# cyt2cl register map
Vendor: Cypress Semiconductor; Series: cyt2cl; File version: 1.0
CPU: CM4 r0p1, little endian, MPU, FPU, VTOR, 3 interrupt priority bits
Registers are 32-bit, read-write, reset 0x0 unless marked. A register's access mark holds for its fields unless they carry their own. Offsets are from the block's base; [hi:lo] are bit positions; lines under a group give offsets from that group; {n}, {i} and the like mark numbered series; <NAME> marks a mode.

## SMIF0 (part 1 of 2) — Serial Memory Interface
Base 0x40420000
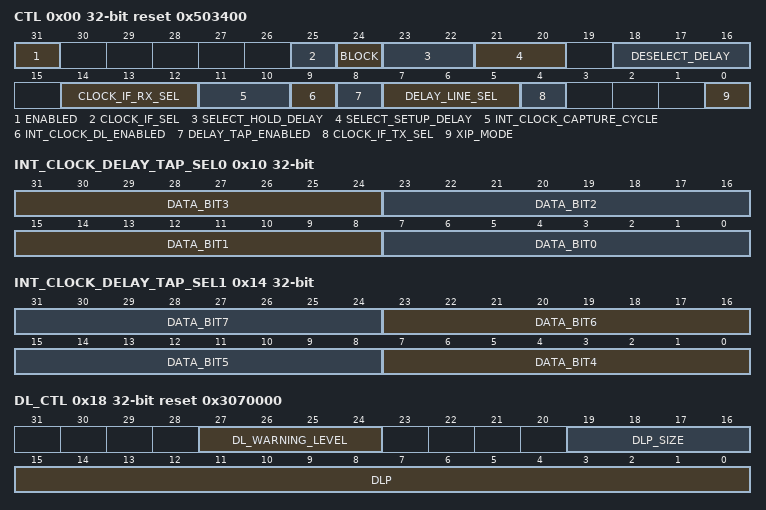
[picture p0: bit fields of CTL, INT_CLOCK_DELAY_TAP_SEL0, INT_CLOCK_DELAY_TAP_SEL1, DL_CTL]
0x00 CTL reset 0x503400 — Control
  [31] ENABLED — IP enable: '0': Disabled. All non-retention registers are reset to their default value when the IP is disabled. When the IP is disabled, the XIP accesses produce AHB-Lite bus errors and AXI error responses. '1': Enabled. Notes: - Before disabling or resetting the IP, SW should ensure that the IP is NOT busy (STATUS.BUSY is '0'), otherwise illegal interface transfers may occur. - After CTL.ENABLED is set to 1 it takes up to 20 clk_if cycles until the memory interface registers are realeased from reset.
    0=DISABLED (N/A); 1=ENABLED (N/A)
  [25] CLOCK_IF_SEL — Specifies the clock source for 'clk_if'. Must be 0 (clk_hf) before entering DeepSleep; can be returned to 1 (clk_pll) afterwards. '0': clk_hf is used to create clk_if '1': clk_pll is used to create clk_if
  [24] BLOCK — Specifies what happens for MMIO interface read accesses to an empty RX data FIFO or to a full TX format/data FIFO. This field is not used for test controller accesses.
    0=BUS_ERROR (0': Generate an AHB-Lite bus error. This option is useful when SW decides to use polling on STATUS.TR_BUSY to determine if a interface transfer is no longer busy (transfer is completed). This option adds SW complexity, but limits the number of AHB-Lite wait states (and limits ISR latency).); 1=WAIT_STATES (1': Introduce wait states. This setting potentially locks up the AHB-Lite infrastructure and may increase the CPU interrupt latency.This option is useful when SW performs TX/RX data FIFO accesses immediately after a command is setup using the TX format FIFO. This option has low SW complexity, but may result in a significant number of AHB-Lite wait states (and may increase ISR latency). This can be particularly true if ARB_MODE=1 and an MMIO access must wait a potentially long time behind a XIP access.)
  [23:22] SELECT_HOLD_DELAY — Specifies the duration between last 'spi_clk_out' edge to 'spi_select_out[]' becomes high/'1'): '0': 0 memory interface clock cycles + min. duration (see below). '1': 1 memory interface clock cycle + min. duration (see below). '2': 2 memory interface clock cycles + min. duration (see below). '3': 3 memory interface clock cycles + min. duration (see below). In addition to the number of cycles selected here there is a min. duration of: - 1/2 memory interface clock cycle (= 1 clk_if cycles) for SDR timing (CLOCK_IF_TX_SEL = 0) - 1/4 memory interface clock cycle (= 1/2 clk_if cycle) for DDR timing (CLOCK_IF_TX_SEL = 1)
  [21:20] SELECT_SETUP_DELAY — Specifies the duration between 'spi_select_out[]' becomes low/'0') to 1st 'spi_clk_out' edge: '0': 0 memory interface clock cycles + min. duration (see below). '1': 1 memory interface clock cycle + min. duration (see below). '2': 2 memory interface clock cycles + min. duration (see below). '3': 3 memory interface clock cycles + min. duration (see below). In addition to the number of cycles selected here there is a min. duration of: - 1 memory interface clock cycle (= 2 clk_if cycle) for SDR timing (CLOCK_IF_TX_SEL = 0) - 1/4 memory interface clock cycle (= 1/2 clk_if cycle) for DDR timing (CLOCK_IF_TX_SEL = 1)
  [18:16] DESELECT_DELAY — Specifies the minimum duration of SPI deselection ('spi_select_out[]' is high/'1') in between SPI transfers: '0': 1 memory interface clock cycle. '1': 2 memory interface clock cycles. '2': 3 memory interface clock cycles. '3': 4 memory interface clock cycles. '4': 5 memory interface clock cycles. '5': 6 memory interface clock cycles. '6': 7 memory interface clock cycles. '7': 8 memory interface clock cycles. During SPI deselection, 'spi_select_out[]' are '1'/inactive, 'spi_data_out[]' are '1' and 'spi_clk_out' is '0'/inactive.
  [14:12] CLOCK_IF_RX_SEL
  [11:10] INT_CLOCK_CAPTURE_CYCLE
  [9] INT_CLOCK_DL_ENABLED — Data Learning Enable for internal RX clock based on Data Learning Pattern. Only applies when CLOCK_IF_RX_SEL = [4..5] for selecting the internal clock based capture scheme and when DELAY_TAP_ENABLED = 1. Must be set to 0 otherwise. '0': Disabled. The delay line tap selections specified in registers INT_CLOCK_DELAY_TAP_SEL0/1 are not modified by HW. '1': Enabled. The delay linle tap selections specified in registers INT_CLOCK_DELAY_TAP_SEL0/1 are modified by HW based on the data learning pattern. From all capture clock delay line taps producing a match between the expected data learning pattern in register DLP and the captured data learning pattern from the memory device the middle one is selected.
  [8] DELAY_TAP_ENABLED — Delay Line Tap Enable. '0': Disabled. The delay line tap selections specified in registers DELAY_TAP_SEL or INT_CLOCK_DELAY_TAP_SEL0/1 are not used. The read data is directly captured by the RX data FIFO capture clock as specified by CLOCK_IF_RX_SEL and INT_CLOCK_CAPTURE_CYCLE. '1': Enabled. The delay line tap selections specified in registers DELAY_TAP_SEL or INT_CLOCK_DELAY_TAP_SEL0/1 are used. If the output / feedback clock based capture scheme (CLOCK_IF_RX_SEL = [0..3]) or the RWDS based capture scheme (CLOCK_IF_RX_SEL = [6..7]) is selected then the register DELAY_TAP_SEL is used to select the capture clock. If the internal clock based capture scheme (CLOCK_IF_RX_SEL = [4..5] and INT_CLOCK_CAPTURE_PRESENT = 1) is selected then the registers INT_CLOCK_DELAY_TAP_SEL0/1 are used to select the capture clock per data bit line (read data is captured by the capture logic and afterwards transferred to the RX data FIFO).
  [7:5] DELAY_LINE_SEL — Specifies the delay line used for RX data capturing with - output / feedback clock based capturing (when CLOCK_IF_RX_SEL = [0..3] and DELAY_TAP_ENABLED = 1) - internal clock based capturing (when CLOCK_IF_RX_SEL = [4..5], INT_CLOCK_CAPTURE_PRESENT = 1 and DELAY_TAP_ENABLED = 1) - RWDS based capturing (when CLOCK_IF_RX_SEL = [6..7])
  [4] CLOCK_IF_TX_SEL — Specifies device interface transmitter clock options. '0': SDR. Memory interface clock 'spihb_clk_out' is divided (by 2) interface clock 'clk_if', memory interface data signals are driven by divided (by 2) interface clock 'clk_if' with different phase than 'spihb_clk_out'. Results in driving memory interface data signals at falling 'spihb_clk_out' edge. '1': DDR. Memory interface clock 'spihb_clk_out' is divided (by 2) inverted interface clock 'clk_if_inv', memory interface data signals are driven with interface clock 'clk_if'. Results in driving memory interface data signals 90 degrees before rising and falling 'spihb_clk_out' edge.
  [0] XIP_MODE — Mode of operation. Note: this field should only be changed when the IP is disabled or when STATUS.BUSY is '0' and SW should not be executing from the XIP interface or MMIO interface.
    0=MMIO_MODE ('0': MMIO mode. Individual MMIO accesses to TX and RX FIFOs are used to generate a sequence of SPI transfers. This mode of operation allows for large flexibility in terms of the SPI transfers that can be generated.); 1=ARB_MODE (''1': Arbitration mode. Arbitrates XIP vs. MMIO accesses such that any ongoing, pending, or 'merged' transactions on XIP always take priority over any MMIO accesses to the device. However, if an MMIO access is in process it cannot be interrupted until it completes (as defined by sending the 'last command' via TX_CMD_MMIO_FIFO_WR). If MMIO accesses are not happening at all, though, then the XIP accesses endure no extra arbitration latency.)
0x04 STATUS ro reset not defined
  [31] BUSY — AHB Cache, AXI interface, cryptography, XIP, device interface, MPC (if present) initialization, or any other key logic busy in the IP: '0': not busy '1': busy When BUSY is '0', the IP can be safely disabled without: - the potential loss of transient write data. - the potential risk of aborting an inflight SPI device interface transfer. - disrupting MPC (if present) initialization When BUSY is '0', the mode of operation (ARB_MODE or MMIO_MODE) can be safely changed.
0x10 INT_CLOCK_DELAY_TAP_SEL0 — Internal Clocking Delay Tap Select Register 0
  [31:24] DATA_BIT3 — Delay line tap selection for the IP's spi_data[3] (note the mapping of spi_data to IO in DEVICE.CTL.DATA_SEL). See DATA_BIT0.
  [23:16] DATA_BIT2 — Delay line tap selection for the IP's spi_data[2] (note the mapping of spi_data to IO in DEVICE.CTL.DATA_SEL). See DATA_BIT0.
  [15:8] DATA_BIT1 — Delay line tap selection for the IP's spi_data[1] (note the mapping of spi_data to IO in DEVICE.CTL.DATA_SEL). See DATA_BIT0.
  [7:0] DATA_BIT0 — Delay line tap selection for the IP's spi_data[0] (note the mapping of spi_data to IO in DEVICE.CTL.DATA_SEL). A value of 0 selects the receive capture clock source specified by CTL.CLOCK_IF_RX_SEL. All other values select a tap of the clock delay line. When the data learning pattern is enabled this value is set by HW.
0x14 INT_CLOCK_DELAY_TAP_SEL1 — Internal Clocking Delay Tap Select Register 1
  [8n-25:8n-32] DATA_BIT{n} (n=4..7) — Delay line tap selection for the IP's spi_data[{n}] (note the mapping of spi_data to IO in DEVICE.CTL.DATA_SEL). See DATA_BIT0.
0x18 DL_CTL reset 0x3070000 — Data Learning Control Register
  [27:24] DL_WARNING_LEVEL — Determines when the DL_WARNING interrupt cause field is set: - DL_WARNING is set when the number of delay line taps resulting to a correctly captured DLP is less than DL_WARNING_LEVEL for at least one input data line Note: To provide a margin in both directions relatively to the selected middle tap at least 3 delay line taps have to result into a correctly captured DLP, i.e. the DL_WARNING_LEVEL has to be set to greater or equal 3.
  [19:16] DLP_SIZE — Size of data learning pattern as such: '0': 1 bit ... '15': 16 bit. If CTL.INT_CLOCK_DL_ENABLED = '1 ' the DLP_SIZE+1 LSBs of the expected data learning patter (DLP[DLP_SIZE:0]) are compared with the data learning pattern generated by the memory device and captured during the last latency / dummy cycles of a memory read transfer. Note: For DDR read data transfers the size of the DLP must be an even number, i.e. DLP_SIZE must be an odd number.
  [15:0] DLP — Data Learning Pattern
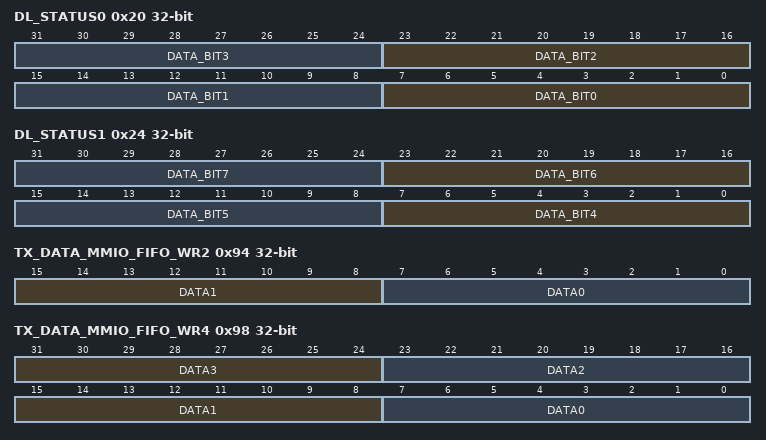
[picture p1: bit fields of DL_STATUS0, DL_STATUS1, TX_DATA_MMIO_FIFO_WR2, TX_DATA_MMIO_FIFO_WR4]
0x20 DL_STATUS0 ro — Data Learning Status Register 0
  [8n+7:8n] DATA_BIT{n} (n=0..3) — Number of delay line taps for the IP's spi_data[{n}] (note the mapping of spi_data to IO in DEVICE.CTL.DATA_SEL) with correctly captured DLP in last read transaction. Legal range: [0, 255].
0x24 DL_STATUS1 ro — Data Learning Status Register 1
  [8n-25:8n-32] DATA_BIT{n} (n=4..7) — Number of delay line taps for the IP's spi_data[{n}] (note the mapping of spi_data to IO in DEVICE.CTL.DATA_SEL) with correctly captured DLP in last read transaction. Legal range: [0, 255].
0x44 TX_CMD_FIFO_STATUS ro — Transmitter command FIFO status
  [3:0] USED4 — Number of entries that are used in the TX command FIFO. Legal range: [0, 8].
0x48 TX_CMD_MMIO_FIFO_STATUS ro — Transmitter command MMIO FIFO status
  [3:0] USED4 — Number of entries that are used in the TX command MMIO FIFO. Legal range: [0, 8].
0x50 TX_CMD_MMIO_FIFO_WR wo — Transmitter command MMIO FIFO write
  [26:0] DATA27
0x80 TX_DATA_MMIO_FIFO_CTL — Transmitter data MMIO FIFO control
  [2:0] TX_TRIGGER_LEVEL — Determines when the TX data MMIO FIFO 'tr_tx_req' trigger is activated: - Trigger is active when TX_DATA_MMIO FIFO_STATUS.USED <= TRIGGER_LEVEL.
0x84 TX_DATA_FIFO_STATUS ro — Transmitter data FIFO status
  [3:0] USED4 — Number of entries that are used in the TX data FIFO. Legal range: [0, 8].
0x88 TX_DATA_MMIO_FIFO_STATUS ro — Transmitter data MMIO FIFO status
  [3:0] USED4 — Number of entries that are used in the TX data MMIO FIFO. Legal range: [0, 8].
0x90 TX_DATA_MMIO_FIFO_WR1 wo — Transmitter data MMIO FIFO write
  [7:0] DATA0 — TX data (written to TX data MMIO FIFO).
0x94 TX_DATA_MMIO_FIFO_WR2 wo — Transmitter data MMIO FIFO write
  [15:8] DATA1 — TX data (written to TX data MMIO FIFO, second byte).
  [7:0] DATA0 — TX data (written to TX data MMIO FIFO, first byte).
0x98 TX_DATA_MMIO_FIFO_WR4 wo — Transmitter data MMIO FIFO write
  [31:24] DATA3 — TX data (written to TX data MMIO FIFO, fourth byte).
  [23:16] DATA2 — TX data (written to TX data MMIO FIFO, third byte).
  [15:8] DATA1 — TX data (written to TX data MMIO FIFO, second byte).
  [7:0] DATA0 — TX data (written to TX data MMIO FIFO, first byte).
0x9C TX_DATA_MMIO_FIFO_WR1ODD wo — Transmitter data MMIO FIFO write
  [7:0] DATA0 — TX data (written to TX data MMIO FIFO).
0xC0 RX_DATA_MMIO_FIFO_CTL — Receiver data MMIO FIFO control
  [2:0] RX_TRIGGER_LEVEL — Determines when RX data FIFO 'tr_rx_req' trigger is activated: - Trigger is active when RX_DATA_MMIO_FIFO_STATUS.USED > TRIGGER_LEVEL.
0xC4 RX_DATA_MMIO_FIFO_STATUS ro — Receiver data MMIO FIFO status
  [3:0] USED4 — Number of entries that are used in the RX data MMIO FIFO. Legal range: [0, 8].
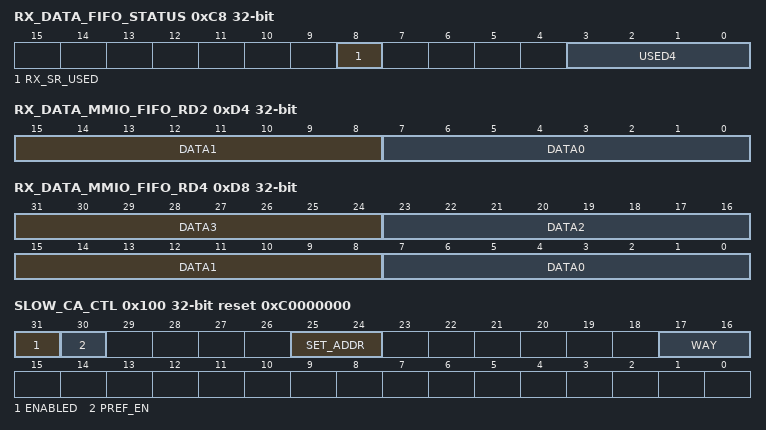
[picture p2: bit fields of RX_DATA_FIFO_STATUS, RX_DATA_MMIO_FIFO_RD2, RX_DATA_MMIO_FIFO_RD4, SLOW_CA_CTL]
0xC8 RX_DATA_FIFO_STATUS ro — Receiver data FIFO status
  [8] RX_SR_USED — Data available in RX Shift Register, i.e. completely read from RX data FIFO.
  [3:0] USED4 — Number of entries that are used in the RX data FIFO. Legal range: [0, 8].
0xD0 RX_DATA_MMIO_FIFO_RD1 ro — Receiver data MMIO FIFO read
  [7:0] DATA0 — RX data (read from RX data FIFO).
0xD4 RX_DATA_MMIO_FIFO_RD2 ro — Receiver data MMIO FIFO read
  [15:8] DATA1 — RX data (read from RX data FIFO, second byte).
  [7:0] DATA0 — RX data (read from RX data FIFO, first byte).
0xD8 RX_DATA_MMIO_FIFO_RD4 ro — Receiver data MMIO FIFO read
  [31:24] DATA3 — RX data (read from RX data FIFO, fourth byte).
  [23:16] DATA2 — RX data (read from RX data FIFO, third byte).
  [15:8] DATA1 — RX data (read from RX data FIFO, second byte).
  [7:0] DATA0 — RX data (read from RX data FIFO, first byte).
0xE0 RX_DATA_MMIO_FIFO_RD1_SILENT ro — Receiver data MMIO FIFO silent read
  [7:0] DATA0 — RX data (read from RX data FIFO).
0x100 SLOW_CA_CTL reset 0xC0000000 — Slow cache control
  [31] ENABLED — Cache enable: '0': Disabled. '1': Enabled.
  [30] PREF_EN — Prefetch enable: '0': Disabled. '1': Enabled. Prefetching requires the cache to be enabled; i.e. ENABLED is '1'.
  [25:24] SET_ADDR — this is for debug purpose only, and should be hidden to customers in technical document
  [17:16] WAY — this is for debug purpose only, and should be hidden to customers in technical document
0x108 SLOW_CA_CMD — Slow cache command
  [0] INV — Cache and prefetch buffer invalidation. SW writes a '1' to clear the cache and prefetch buffer. The cache's LRU structure is also reset to its default state. Note, A write access will invalidate the prefetch buffer automatically in hardware. A write access should invalidate both fast and slow caches, by firmware. Note, firmware should invalidate the cache and prefetch buffer only when STATUS.BUSY is '0'.
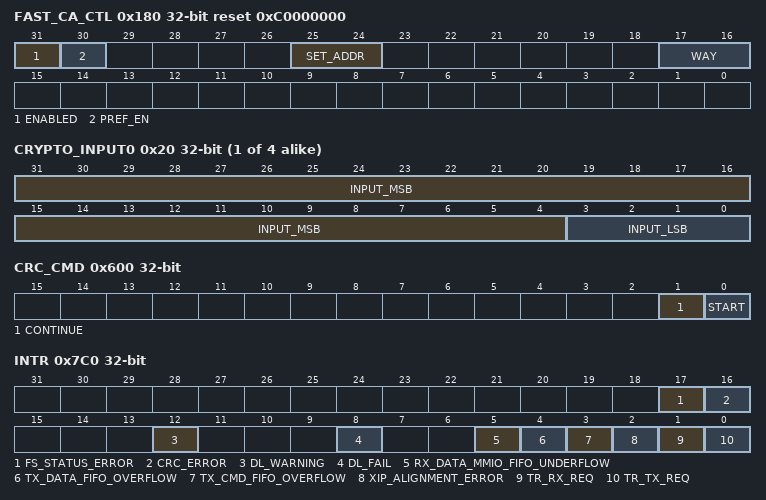
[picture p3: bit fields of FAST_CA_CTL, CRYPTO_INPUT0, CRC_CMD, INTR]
0x180 FAST_CA_CTL reset 0xC0000000 — Fast cache control
  [31] ENABLED — See SLOW_CA_CTL.ENABLED.
  [30] PREF_EN — See SLOW_CA_CTL.PREF_EN.
  [25:24] SET_ADDR — this is for debug purpose only, and should be hidden to customers in technical document
  [17:16] WAY — this is for debug purpose only, and should be hidden to customers in technical document
0x188 FAST_CA_CMD — Fast cache command
  [0] INV — See SLOW_CA_CMD.INV.
{0x200+0x80*i} SMIF_CRYPTO[{i}] (i=0..3) group — Cryptography registers (one set for each key)
  0x00 CRYPTO_CMD — Cryptography command
    [0] START — SW sets this field to '1' to start an AES-128 forward block cipher operation (on CRYPTO_INPUT0-3). HW sets this field to '0' to indicate that the operation has completed. Once completed, the result of the operation can be read from CRYPTO_OUTPUT0, ..., CRYPTO_OUTPUT3. The operation takes roughly 13 clk_mem clock cycles. This register is only applicable for MMIO accesses and only in MMIO_MODE. XIP accesses are encrypted on-the-fly in ARB_MODE and thus do not use this register. Because XIP has exclusive access to the crypto engine in ARB_MODE, MMIO encryption is not available in that mode. As such if encryption is needed for MMIO accesses in ARB_MODE that encryption must be done by other means (i.e., chip level crypto).
  0x04 CRYPTO_ADDR — Cryptography base address
    [31:8] ADDR — Only applies to XIP accesses. Specifies the base address of the memory region that will have cryptography applied on XIP accesses with a unique key. If this region overlaps with another key's region, the lower numbered key is used (i.e., crypto key 0 has the highest priority). If the region is 2^m Bytes, ADDR MUST be a multiple of 2^m. The most significant bit fields are constants and set based on the SMIF_XIP_ADDR parameter. The most significant bits are identified on the SMIF_XIP_MASK parameter. E.g., if SMIF_XIP_MASK is 0xff00:0000 (16 MB XIP memory region), ADDR[31:24] = SMIF_XIP_ADDR[31:24]. Note that in order for cryptogrpahy to be applied the DEVICE.CTL.CRYPTO_EN must be set to 1 as well for any devices that share this region.
  0x08 CRYPTO_MASK — Cryptography mask
    [31:8] MASK — Only applies to XIP accesses. Specifies the size of the memory region whose base address is determined by CRYPTO_ADDR. All '1' bits are used to compare the incoming transfer request address A[31:0] with the address as specified in CRYPTO_ADDR.ADDR: Address A is in the cryptography region when (A[31:8] & MASK[31:8]) == CRYPTO_ADDR.ADDR[31:8]. The most significant bit fields are constants and set to'1'. The most significant bits are identified on the SMIF_XIP_MASK parameter. E.g., if SMIF_XIP_MASK is 0xff00:0000 (16 MB XIP memory region), MASK[31:24] = 0xff.
  0x0C CRYPTO_SUBREGION — Cryptography subregion disable
    [7:0] SUBREGION_DISABLE — Only applies to XIP accesses. The cryptography region for this key as determined by CRYPTO_ADDR and CRYPTO_MASK is further divided into 8 equal subregions. e.g., if a 1 MB region is specified then the 8 subregions will be 128 KB. If SUBREGION_DISABLE=0 then cryptography will be performed on that subregion (assuming any associated DEVICE.CTL.CRYPTO_EN=1). Otherwise if SUBREGION_DISABLE=1 then cryptography is not applied. Note that setting all SUBREGION_DISABLE bits to 1 will effectively disable this key. The encryption decision and the associated key are locked in at the beginning of a memory access and will apply until the end of such atomic accesses. Therefore, it is the user's responsibility to ensure memory accesses do not span across (sub)regions that have different keys and/or cypto enabled/disabled differently across such (sub)regions.
  0x20 CRYPTO_INPUT0 reset not defined — Cryptography input 0
    [31:4] INPUT_MSB — Plaintext PT[31:4] = CRYPTO_INPUT0.INPUT_MSB.
    [3:0] INPUT_LSB — Plaintext PT[3:0] = CRYPTO_INPUT0.INPUT_LSB.
  {0x20+4j} CRYPTO_INPUT{j} reset not defined (j=1..3) — Cryptography input {j}
    [31:0] INPUT — Plaintext PT[{32j+31}:{32j}] = CRYPTO_INPUT{j}.INPUT[31:0].
  {0x40+4j} CRYPTO_KEY{j} wo reset not defined (j=0..3) — Cryptography key {j}
    [31:0] KEY — Four Bytes of the key KEY[{32j+31}:{32j}] = CRYPTO_KEY{j}.KEY[31:0].
  {0x60+4j} CRYPTO_OUTPUT{j} reset not defined (j=0..3) — Cryptography output {j}
    [31:0] OUTPUT — Four Bytes of the ciphertext CT[{32j+31}:{32j}] = CRYPTO_OUTPUT{j}.OUTPUT[31:0].
0x600 CRC_CMD — CRC Command
  [1] CONTINUE — SW sets this field to '1' to continue a CRC calculation over the 64 CRC input bits provided in CRC_INPUT0 and CRC_INPUT1, using the current CRC output in CRC_OUTPUT as CRC feedback. HW sets this field to '0' to indicate that the operation has completed. Once completed, the result of the operation can be read from CRC_OUTPUT. This command is used to perform a CRC calculation over more than 64 intput bits. For example a CRC calculation over 128 bits is done by writing the first 64 input bits to CRC_INPUT0/1, performing a START command, writing the second 64 input bits to CRC_INPUT0/1, performing a CONTINUE command and reading the CRC result from CRC_OUTPUT. For a CRC calculation of even more input bits the CONTINUE command has to be used multiple times. This register is only applicable for MMIO accesses.
  [0] START — SW sets this field to '1' to start a CRC calculation over the 64 CRC input bits provided in CRC_INPUT0 and CRC_INPUT1, using 0xFF as CRC feedback. HW sets this field to '0' to indicate that the operation has completed. Once completed, the result of the operation can be read from CRC_OUTPUT. A CRC calculation over 64 bits is done by writing the 64 input bits to CRC_INPUT0/1, performing a START command and reading the CRC result from CRC_OUTPUT. This register is only applicable for MMIO accesses.
0x620 CRC_INPUT0 reset not defined
  [31:0] INPUT — Lower 32 input bits to the CRC engine.
0x624 CRC_INPUT1 reset not defined
  [31:0] INPUT — Higher 32 input bits to the CRC engine.
0x640 CRC_OUTPUT ro reset 0xFF
  [7:0] CRC_OUTPUT — CRC engine output.
0x7C0 INTR — Interrupt register
  [17] FS_STATUS_ERROR — Functional Safety Status Error. A read transfer Functional Safety Status check failed (see definition in DEVICE_ver2.RD_CRC_CTL.STATUS_CHECK_MASK and DEVICE_ver2.RD_CRC_CTL.STATUS_CHECK_MASK_POL).
  [16] CRC_ERROR — CRC Error. A read transfer data CRC check failed.
  [12] DL_WARNING — Data Learning Warning (for at least one input data line less then DLP.DL_WARNING_LEVEL delay line taps resulted in a correct DLP capturing when CTL.INT_CLOCK_DL_ENABLED = 1). This interrupt will be suppressed, though, if DL_FAIL also occurs during the same DLP evaluation cycle.
  [8] DL_FAIL — Data Learning Failed (no DLP match found on at least one of the input data lines when CTL.INT_CLOCK_DL_ENABLED = 1).
  [5] RX_DATA_MMIO_FIFO_UNDERFLOW — Activated on an AHB-Lite read transfer from the RX data MMIO FIFO (RX_DATA_MMIO_FIFO_RD1, RX_DATA_MMIO_FIFO_RD2, RX_DATA_MMIO_FIFO_RD4) with not enough entries available. Only activated for NON test bus controller transfers.
  [4] TX_DATA_FIFO_OVERFLOW — Activated on an AHB-Lite write transfer to the TX data MMIO FIFO (TX_DATA_MMIO_FIFO_WR1, TX_DATA_MMIO_FIFO_WR2, TX_DATA_MMIO_FIFO_WR4, TX_DATA_MMIO_FIFO_WR1ODD) with not enough free entries available.
  [3] TX_CMD_FIFO_OVERFLOW — Activated on an AHB-Lite write transfer to the TX command MMIO FIFO (TX_CMD_MMIO_FIFO_WR) with not enough free entries available.
  [2] XIP_ALIGNMENT_ERROR — Activated on a XIP access, when: - a write transfer is requested and - Dual-Quad SPI mode (selected device's ADDR_CTL.DIV2 is '1') is selected or - Octal SPI DDR mode (selected device's DATA_CTL.DDR_MODE = '1' and DATA_CTL.WIDTH = '3') or Hyperbus mode (selected device's ADDR_CTL.SIZE3 = '7') is selected without memory write byte masking (selected device's WR_DUMMY_CTL.RWDS_EN = '0') and - the AHB-Lite / AXI bus transfer address is not a multiple of '2' or - the requested AHB-Lite / AXI bus transfer size is NOT a multiple of '2'. Additionally, it is activated on a XIP access when the selected memory device does not support write byte masking (WR_DUMMY_CTL.RWDS_EN=0) and an AXI transfer occurs with not all of the AXI write strobes ('wstrb') enabled according to the transfer size ('assize'). Note: In dual-quad SPI mode (ADDR_CTL.DIV is '1'), each memory device contributes a 4-bit nibble for read data or write data. Write accesses are only possible if the request address is a multiple of 2 and the number of requested Bytes is a multiple of 2. Octal SPI DDR mode or Hyperbus mode are 16-bit word based protocols, writing single bytes is only possible when write byte masking is supported (via RWDS). Read accesses are always possible by extending the transfer size and / or aligning the address as needed and discarding the non-relevant byte(s).
  [1] TR_RX_REQ — Activated when a RX data MMIO FIFO trigger 'tr_rx_req' is activated.
  [0] TR_TX_REQ — Activated when a TX data MMIO FIFO trigger 'tr_tx_req' is activated.
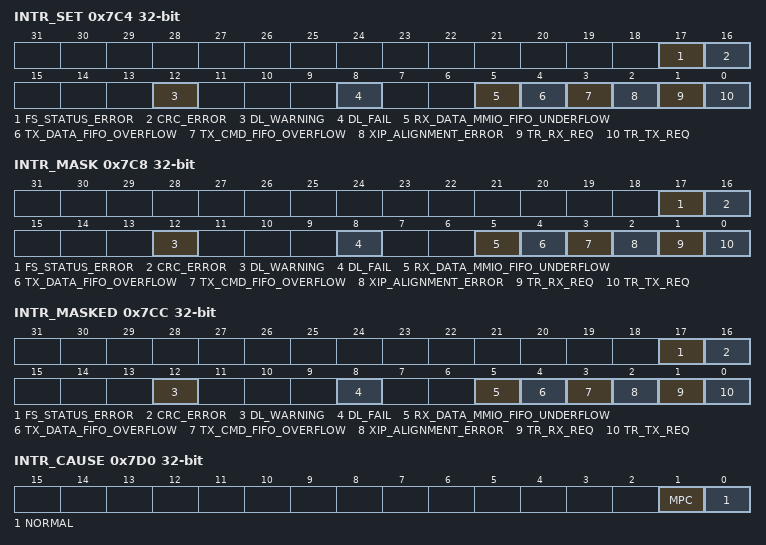
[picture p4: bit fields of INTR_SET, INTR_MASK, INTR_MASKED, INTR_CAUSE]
0x7C4 INTR_SET — Interrupt set register
  [17] FS_STATUS_ERROR — Write with '1' to set corresponding bit in interrupt request register.
  [16] CRC_ERROR — Write with '1' to set corresponding bit in interrupt request register.
  [12] DL_WARNING — Write with '1' to set corresponding bit in interrupt request register.
  [8] DL_FAIL — Write with '1' to set corresponding bit in interrupt request register.
  [5] RX_DATA_MMIO_FIFO_UNDERFLOW — Write with '1' to set corresponding bit in interrupt request register.
  [4] TX_DATA_FIFO_OVERFLOW — Write with '1' to set corresponding bit in interrupt request register.
  [3] TX_CMD_FIFO_OVERFLOW — Write with '1' to set corresponding bit in interrupt request register.
  [2] XIP_ALIGNMENT_ERROR — Write with '1' to set corresponding bit in interrupt request register.
  [1] TR_RX_REQ — Write with '1' to set corresponding bit in interrupt request register.
  [0] TR_TX_REQ — Write with '1' to set corresponding bit in interrupt request register.
0x7C8 INTR_MASK — Interrupt mask register
  [17] FS_STATUS_ERROR — Mask bit for corresponding bit in interrupt request register.
  [16] CRC_ERROR — Mask bit for corresponding bit in interrupt request register.
  [12] DL_WARNING — Mask bit for corresponding bit in interrupt request register.
  [8] DL_FAIL — Mask bit for corresponding bit in interrupt request register.
  [5] RX_DATA_MMIO_FIFO_UNDERFLOW — Mask bit for corresponding bit in interrupt request register.
  [4] TX_DATA_FIFO_OVERFLOW — Mask bit for corresponding bit in interrupt request register.
  [3] TX_CMD_FIFO_OVERFLOW — Mask bit for corresponding bit in interrupt request register.
  [2] XIP_ALIGNMENT_ERROR — Mask bit for corresponding bit in interrupt request register.
  [1] TR_RX_REQ — Mask bit for corresponding bit in interrupt request register.
  [0] TR_TX_REQ — Mask bit for corresponding bit in interrupt request register.
0x7CC INTR_MASKED ro — Interrupt masked register
  [17] FS_STATUS_ERROR — Logical and of corresponding request and mask bits.
  [16] CRC_ERROR — Logical and of corresponding request and mask bits.
  [12] DL_WARNING — Logical and of corresponding request and mask bits.
  [8] DL_FAIL — Logical and of corresponding request and mask bits.
  [5] RX_DATA_MMIO_FIFO_UNDERFLOW — Logical and of corresponding request and mask bits.
  [4] TX_DATA_FIFO_OVERFLOW — Logical and of corresponding request and mask bits.
  [3] TX_CMD_FIFO_OVERFLOW — Logical and of corresponding request and mask bits.
  [2] XIP_ALIGNMENT_ERROR — Logical and of corresponding request and mask bits.
  [1] TR_RX_REQ — Logical and of corresponding request and mask bits.
  [0] TR_TX_REQ — Logical and of corresponding request and mask bits.
0x7D0 INTR_CAUSE ro — Distinguishes normal vs. MPC interrupt
  [1] MPC — Reflects the state of interrupt_mpc (which is the OR of the elements in the MPC'S INTR_MASKED)
  [0] NORMAL — Reflects the state of interrupt_normal (which is the OR of the elements in the normal INTR_MASKED)
